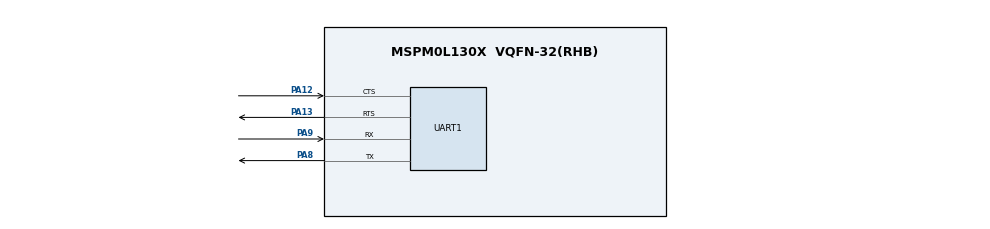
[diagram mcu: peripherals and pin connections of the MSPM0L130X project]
// @cliArgs --device "MSPM0L130X" --package "VQFN-32(RHB)" --part "Default"
// @cliArgs --board /ti/boards/LP_MSPM0L1306 --rtos nortos

/**
 * Import the modules used in this configuration.
 */
const UART   = scripting.addModule("/ti/driverlib/UART", {}, false);
const UART1  = UART.addInstance();
const GPIO   = scripting.addModule("/ti/driverlib/GPIO", {}, false);
const GPIO1  = GPIO.addInstance();

/**
 * Write custom configuration values to the imported modules.
 */

UART1.$name = "UART_0";
UART1.profile = "CONFIG_PROFILE_3";
UART1.targetBaudRate = 115200;
UART1.enableFIFO = true;
UART1.peripheral.$assign = "UART0";

UART1.peripheral.txPin.$assign = "PA8";
UART1.peripheral.rxPin.$assign = "PA9";
UART1.peripheral.rtsPin.$assign = "PA13";
UART1.peripheral.ctsPin.$assign = "PA12";

const Board = scripting.addModule("/ti/driverlib/Board", {}, false);
const SYSCTL = scripting.addModule("/ti/driverlib/SYSCTL");
SYSCTL.clockTreeEn = true;

GPIO1.$name                                 = "GPIO_LEDS";
GPIO1.associatedPins.create(2);
GPIO1.associatedPins[0].$name               = "USER_LED_1";
GPIO1.associatedPins[0].assignedPort        = "PORTA";
GPIO1.associatedPins[0].assignedPortSegment = "Lower";
GPIO1.associatedPins[0].assignedPin         = "0";
GPIO1.associatedPins[0].initialValue        = "SET";
GPIO1.associatedPins[1].$name               = "USER_TEST";
GPIO1.associatedPins[1].assignedPort        = "PORTA";
GPIO1.associatedPins[1].assignedPortSegment = "Lower";
GPIO1.associatedPins[1].initialValue        = "SET";
GPIO1.associatedPins[1].assignedPin         = "1";
